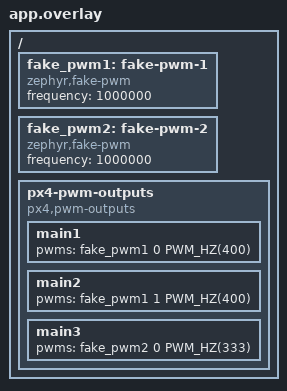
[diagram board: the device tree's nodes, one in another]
#include <zephyr/dt-bindings/pwm/pwm.h>

/ {
	/* timers for the 400 Hz and 333 Hz outputs, whose cycles are microseconds */
	fake_pwm1: fake-pwm-1 {
		compatible = "zephyr,fake-pwm";
		#pwm-cells = <2>;
		frequency = <1000000>;
	};

	fake_pwm2: fake-pwm-2 {
		compatible = "zephyr,fake-pwm";
		#pwm-cells = <2>;
		frequency = <1000000>;
	};

	px4-pwm-outputs {
		compatible = "px4,pwm-outputs";

		main1 {
			pwms = <&fake_pwm1 0 PWM_HZ(400)>;
		};

		main2 {
			pwms = <&fake_pwm1 1 PWM_HZ(400)>;
		};

		main3 {
			pwms = <&fake_pwm2 0 PWM_HZ(333)>;
		};
	};
};
